# TM4C123AH6PM register map
Vendor: Texas Instruments; File version: 11073
CPU: CM4 r1p2, little endian, no MPU, no FPU, 0x3 interrupt priority bits, 0x0 interrupts
Registers are 32-bit, read-write, no defined reset value unless marked. A register's access mark holds for its fields unless they carry their own. Offsets are from the block's base; [hi:lo] are bit positions; {n}, {i} and the like mark numbered series.

## SSI0 — Register map for SSI0 peripheral
Base 0x40008000; register names take the prefix SSI0
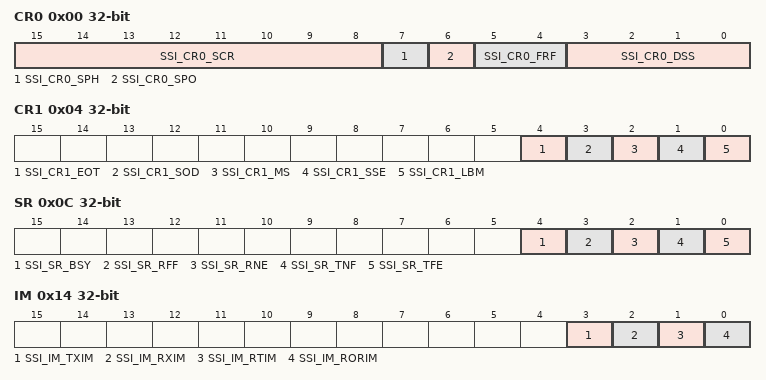
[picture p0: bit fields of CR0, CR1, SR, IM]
0x00 CR0 — SSI Control 0
  [15:8] SSI_CR0_SCR — SSI Serial Clock Rate
  [7] SSI_CR0_SPH — SSI Serial Clock Phase
  [6] SSI_CR0_SPO — SSI Serial Clock Polarity
  [5:4] SSI_CR0_FRF — SSI Frame Format Select
    0=SSI_CR0_FRF_MOTO (Freescale SPI Frame Format); 1=SSI_CR0_FRF_TI (Texas Instruments Synchronous Serial Frame Format); 2=SSI_CR0_FRF_NMW (MICROWIRE Frame Format)
  [3:0] SSI_CR0_DSS — SSI Data Size Select
    {v}={v+1}-bit data (v=3..15)
0x04 CR1 — SSI Control 1
  [4] SSI_CR1_EOT — End of Transmission
  [3] SSI_CR1_SOD — SSI Slave Mode Output Disable
  [2] SSI_CR1_MS — SSI Master/Slave Select
  [1] SSI_CR1_SSE — SSI Synchronous Serial Port Enable
  [0] SSI_CR1_LBM — SSI Loopback Mode
0x08 DR — SSI Data
  [15:0] SSI_DR_DATA — SSI Receive/Transmit Data
0x0C SR — SSI Status
  [4] SSI_SR_BSY — SSI Busy Bit
  [3] SSI_SR_RFF — SSI Receive FIFO Full
  [2] SSI_SR_RNE — SSI Receive FIFO Not Empty
  [1] SSI_SR_TNF — SSI Transmit FIFO Not Full
  [0] SSI_SR_TFE — SSI Transmit FIFO Empty
0x10 CPSR — SSI Clock Prescale
  [7:0] SSI_CPSR_CPSDVSR — SSI Clock Prescale Divisor
0x14 IM — SSI Interrupt Mask
  [3] SSI_IM_TXIM — SSI Transmit FIFO Interrupt Mask
  [2] SSI_IM_RXIM — SSI Receive FIFO Interrupt Mask
  [1] SSI_IM_RTIM — SSI Receive Time-Out Interrupt Mask
  [0] SSI_IM_RORIM — SSI Receive Overrun Interrupt Mask
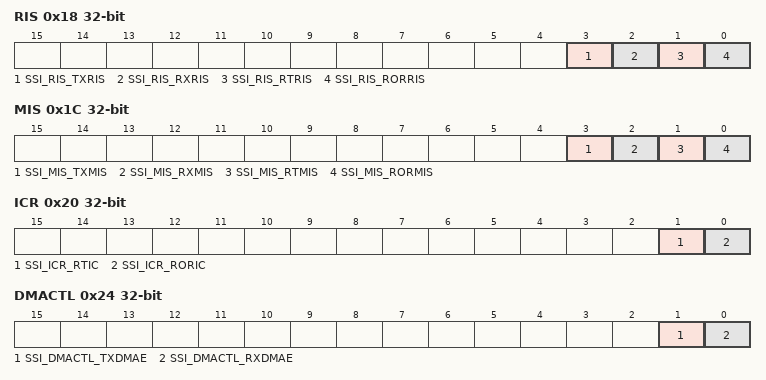
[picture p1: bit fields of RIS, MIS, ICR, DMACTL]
0x18 RIS — SSI Raw Interrupt Status
  [3] SSI_RIS_TXRIS — SSI Transmit FIFO Raw Interrupt Status
  [2] SSI_RIS_RXRIS — SSI Receive FIFO Raw Interrupt Status
  [1] SSI_RIS_RTRIS — SSI Receive Time-Out Raw Interrupt Status
  [0] SSI_RIS_RORRIS — SSI Receive Overrun Raw Interrupt Status
0x1C MIS — SSI Masked Interrupt Status
  [3] SSI_MIS_TXMIS — SSI Transmit FIFO Masked Interrupt Status
  [2] SSI_MIS_RXMIS — SSI Receive FIFO Masked Interrupt Status
  [1] SSI_MIS_RTMIS — SSI Receive Time-Out Masked Interrupt Status
  [0] SSI_MIS_RORMIS — SSI Receive Overrun Masked Interrupt Status
0x20 ICR wo — SSI Interrupt Clear
  [1] SSI_ICR_RTIC — SSI Receive Time-Out Interrupt Clear
  [0] SSI_ICR_RORIC — SSI Receive Overrun Interrupt Clear
0x24 DMACTL — SSI DMA Control
  [1] SSI_DMACTL_TXDMAE — Transmit DMA Enable
  [0] SSI_DMACTL_RXDMAE — Receive DMA Enable
0xFC8 CC — SSI Clock Configuration
  [3:0] SSI_CC_CS — SSI Baud Clock Source
    0=SSI_CC_CS_SYSPLL (Either the system clock (if the PLL bypass is in effect) or the PLL output (default)); 5=SSI_CC_CS_PIOSC (PIOSC)

## SSI1 — Register map for SSI0 peripheral
Base 0x40009000; register names take the prefix SSI1
Registers as SSI0.

## SSI2 — Register map for SSI0 peripheral
Base 0x4000A000; register names take the prefix SSI2
Registers as SSI0.

## SSI3 — Register map for SSI0 peripheral
Base 0x4000B000; register names take the prefix SSI3
Registers as SSI0.

## QEI0 — Register map for QEI0 peripheral
Base 0x4002C000; register names take the prefix QEI0
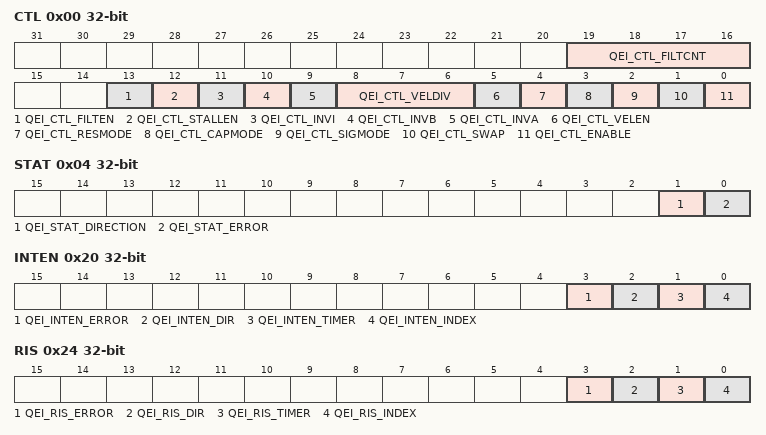
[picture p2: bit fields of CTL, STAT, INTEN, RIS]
0x00 CTL — QEI Control
  [19:16] QEI_CTL_FILTCNT — Input Filter Prescale Count
  [13] QEI_CTL_FILTEN — Enable Input Filter
  [12] QEI_CTL_STALLEN — Stall QEI
  [11] QEI_CTL_INVI — Invert Index Pulse
  [10] QEI_CTL_INVB — Invert PhB
  [9] QEI_CTL_INVA — Invert PhA
  [8:6] QEI_CTL_VELDIV — Predivide Velocity
    0=QEI clock /1; 1=QEI clock /2; 2=QEI clock /4; 3=QEI clock /8; 4=QEI clock /16; 5=QEI clock /32; 6=QEI clock /64; 7=QEI clock /128
  [5] QEI_CTL_VELEN — Capture Velocity
  [4] QEI_CTL_RESMODE — Reset Mode
  [3] QEI_CTL_CAPMODE — Capture Mode
  [2] QEI_CTL_SIGMODE — Signal Mode
  [1] QEI_CTL_SWAP — Swap Signals
  [0] QEI_CTL_ENABLE — Enable QEI
0x04 STAT — QEI Status
  [1] QEI_STAT_DIRECTION — Direction of Rotation
  [0] QEI_STAT_ERROR — Error Detected
0x08 POS — QEI Position
  [31:0] QEI_POS — Current Position Integrator Value
0x0C MAXPOS — QEI Maximum Position
  [31:0] QEI_MAXPOS — Maximum Position Integrator Value
0x10 LOAD — QEI Timer Load
  [31:0] QEI_LOAD — Velocity Timer Load Value
0x14 TIME — QEI Timer
  [31:0] QEI_TIME — Velocity Timer Current Value
0x18 COUNT — QEI Velocity Counter
  [31:0] QEI_COUNT — Velocity Pulse Count
0x1C SPEED — QEI Velocity
  [31:0] QEI_SPEED — Velocity
0x20 INTEN — QEI Interrupt Enable
  [3] QEI_INTEN_ERROR — Phase Error Interrupt Enable
  [2] QEI_INTEN_DIR — Direction Change Interrupt Enable
  [1] QEI_INTEN_TIMER — Timer Expires Interrupt Enable
  [0] QEI_INTEN_INDEX — Index Pulse Detected Interrupt Enable
0x24 RIS — QEI Raw Interrupt Status
  [3] QEI_RIS_ERROR — Phase Error Detected
  [2] QEI_RIS_DIR — Direction Change Detected
  [1] QEI_RIS_TIMER — Velocity Timer Expired
  [0] QEI_RIS_INDEX — Index Pulse Asserted
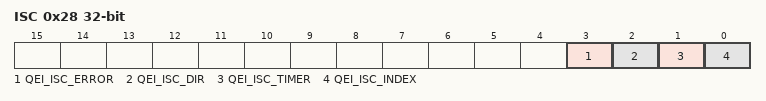
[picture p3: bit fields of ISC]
0x28 ISC — QEI Interrupt Status and Clear
  [3] QEI_ISC_ERROR — Phase Error Interrupt
  [2] QEI_ISC_DIR — Direction Change Interrupt
  [1] QEI_ISC_TIMER — Velocity Timer Expired Interrupt
  [0] QEI_ISC_INDEX — Index Pulse Interrupt

## QEI1 — Register map for QEI0 peripheral
Base 0x4002D000; register names take the prefix QEI1
Registers as QEI0.
